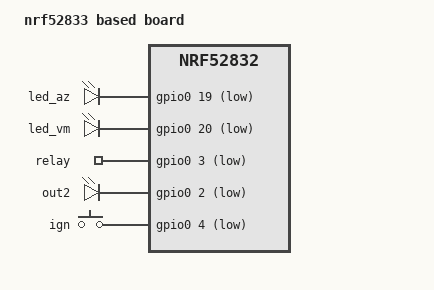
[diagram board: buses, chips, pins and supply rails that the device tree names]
/dts-v1/;
#include <nordic/nrf52832_qfaa.dtsi>
#include "nrf52832_slm-pinctrl.dtsi"

/ {
	model = "nrf52833 based board";
	compatible = "queo,nrf52832_slm";

	chosen {
		zephyr,sram = &sram0;
		zephyr,flash = &flash0;
		zephyr,code-partition = &slot0_partition;
	};

	leds {
		compatible = "gpio-leds";
		led1: led_1 {
			label = "led_az";
			gpios = <&gpio0 19 (GPIO_ACTIVE_LOW)>;
		};

		led0: led_0 {
			label = "led_vm";
			gpios = <&gpio0 20 (GPIO_ACTIVE_LOW)>;
		};

		led2: led_2 {
			label = "relay";
			gpios = <&gpio0 3 (GPIO_ACTIVE_LOW)>;
		};

		led3: led_3 {
			label = "out2";
			gpios = <&gpio0 2 (GPIO_ACTIVE_LOW)>;
		};
	};

	buttons {
		compatible = "gpio-keys";
		button0: button_0 {
			label = "ign";
			gpios = <&gpio0 4 (GPIO_ACTIVE_LOW | GPIO_PULL_UP)>;
			zephyr,code = <INPUT_KEY_0>;
		};
	};

	/* These aliases are provided for compatibility with samples */
	aliases {
		led0 = &led0;
		led1 = &led1;
		led2 = &led2;
		led3 = &led3;
		sw0 = &button0;
	};
};

&flash0 {
	partitions {
		compatible = "fixed-partitions";
		#address-cells = <1>;
		#size-cells = <1>;

		boot_partition: partition@0 {
			label = "mcuboot";
			reg = <0x00000000 DT_SIZE_K(48)>;
		};

		slot0_partition: partition@c000 {
			label = "image-0";
			reg = <0x0000c000 DT_SIZE_K(220)>;
		};

		slot1_partition: partition@43000 {
			label = "image-1";
			reg = <0x00043000 DT_SIZE_K(220)>;
		};

		storage_partition: partition@7a000 {
			label = "storage";
			reg = <0x0007a000 DT_SIZE_K(24)>;
		};
	};
};
&gpio0 {
	status = "okay";
};

&gpiote {
	status = "okay";
};

&uicr {
	gpio-as-nreset;
};


